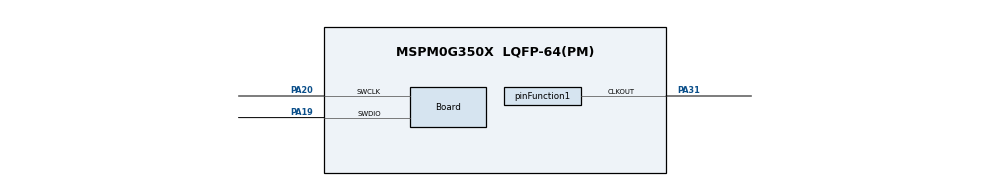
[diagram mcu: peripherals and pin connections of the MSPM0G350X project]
/**
 * @cliArgs --device "MSPM0G350X" --package "LQFP-64(PM)" --part "Default" --product "mspm0_sdk@2.01.00.03"
 * @versions {"tool":"1.20.0+3587"}
 */

/**
 * Import the modules used in this configuration.
 */
const GPIO          = scripting.addModule("/ti/driverlib/GPIO", {}, false);
const GPIO1         = GPIO.addInstance();
const SYSCTL        = scripting.addModule("/ti/driverlib/SYSCTL");
const ProjectConfig = scripting.addModule("/ti/project_config/ProjectConfig");

/**
 * Write custom configuration values to the imported modules.
 */
const gate4  = system.clockTree["EXCLKGATE"];
gate4.enable = true;

const mux3       = system.clockTree["EXCLKMUX"];
mux3.inputSelect = "EXCLKMUX_HFCLK";

const mux4       = system.clockTree["EXHFMUX"];
mux4.inputSelect = "EXHFMUX_XTAL";

const mux5       = system.clockTree["EXLFMUX"];
mux5.inputSelect = "EXLFMUX_XTAL";

const mux8       = system.clockTree["HSCLKMUX"];
mux8.inputSelect = "HSCLKMUX_HFCLK";

const mux9       = system.clockTree["LFXTMUX"];
mux9.inputSelect = "LFXTMUX_TRUE";

const mux10       = system.clockTree["MFPCLKMUX"];
mux10.inputSelect = "MFPCLKMUX_HFCLK";

const pinFunction1                        = system.clockTree["CLKOUT"];
pinFunction1.enable                       = true;
pinFunction1.peripheral.clkOutPin.$assign = "PA31";

const pinFunction4        = system.clockTree["HFXT"];
pinFunction4.inputFreq    = 20;
pinFunction4.enable       = true;
pinFunction4.HFCLKMonitor = true;
pinFunction4.HFXTStartup  = 40;

const pinFunction6              = system.clockTree["LFXT"];
pinFunction6.LFCLKMonitorEnable = true;
pinFunction6.enable             = true;
pinFunction6.inputFreq          = 32.768;

GPIO1.$name                          = "GPIO_LEDS";
GPIO1.port                           = "PORTB";
GPIO1.associatedPins.create(3);
GPIO1.associatedPins[0].assignedPin  = "22";
GPIO1.associatedPins[0].initialValue = "SET";
GPIO1.associatedPins[0].$name        = "LED_Blue";
GPIO1.associatedPins[1].assignedPin  = "21";
GPIO1.associatedPins[1].initialValue = "SET";
GPIO1.associatedPins[1].$name        = "LED_Red";
GPIO1.associatedPins[2].assignedPin  = "20";
GPIO1.associatedPins[2].$name        = "LED_Green";

const Board                       = scripting.addModule("/ti/driverlib/Board", {}, false);
Board.peripheral.$assign          = "DEBUGSS";
Board.peripheral.swclkPin.$assign = "PA20";
Board.peripheral.swdioPin.$assign = "PA19";

SYSCTL.clockTreeEn           = true;
SYSCTL.HFCLKSource           = "HFXT";
SYSCTL.forceDefaultClkConfig = true;

ProjectConfig.deviceSpin = "MSPM0G3507";
scripting.suppress("Migrating requires going through the Switch Board or Device menu in the Device View section\\.", ProjectConfig, "deviceSpin");

/**
 * Pinmux solution for unlocked pins/peripherals. This ensures that minor changes to the automatic solver in a future
 * version of the tool will not impact the pinmux you originally saw.  These lines can be completely deleted in order to
 * re-solve from scratch.
 */
pinFunction1.peripheral.$suggestSolution           = "SYSCTL";
pinFunction4.peripheral.$suggestSolution           = "SYSCTL";
pinFunction4.peripheral.hfxInPin.$suggestSolution  = "PA5";
pinFunction4.peripheral.hfxOutPin.$suggestSolution = "PA6";
pinFunction6.peripheral.$suggestSolution           = "SYSCTL";
pinFunction6.peripheral.lfxInPin.$suggestSolution  = "PA3";
pinFunction6.peripheral.lfxOutPin.$suggestSolution = "PA4";
GPIO1.associatedPins[0].pin.$suggestSolution       = "PB22";
GPIO1.associatedPins[1].pin.$suggestSolution       = "PB21";
GPIO1.associatedPins[2].pin.$suggestSolution       = "PB20";
